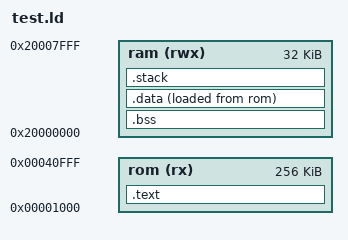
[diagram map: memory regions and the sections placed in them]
MEMORY
{
  rom      (rx)  : ORIGIN = 0x00001000, LENGTH = 0x00040000
  ram      (rwx) : ORIGIN = 0x20000000, LENGTH = 0x00008000
}

STACK_SIZE = 0x2000;

/* Section Definitions */
SECTIONS
{
    .text :
    {
        KEEP(*(.vectors .vectors.*))
        *(.text*)
        *(.rodata*)
        *(.parameter*)
    } > rom

    /* .bss section which is used for uninitialized data */
    .bss (NOLOAD) :
    {
        *(.bss*)
        *(COMMON)
    } > ram

    .data :
    {
        *(.data*);
    } > ram AT >rom

    /* stack section */
    .stack (NOLOAD):
    {
        . = ALIGN(8);
        . = . + STACK_SIZE;
        . = ALIGN(8);
    } > ram

    _end = . ;
}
